# STM32H7RSxx register map
File version: 0.2
CPU: CM7 r0p1, little endian, MPU, FPU, 4 interrupt priority bits
Registers are 32-bit, read-write, reset 0x0 unless marked. A register's access mark holds for its fields unless they carry their own. Offsets are from the block's base; [hi:lo] are bit positions; {n}, {i} and the like mark numbered series.

## PSSI — Parallel synchronous slave interface
Base 0x48000400
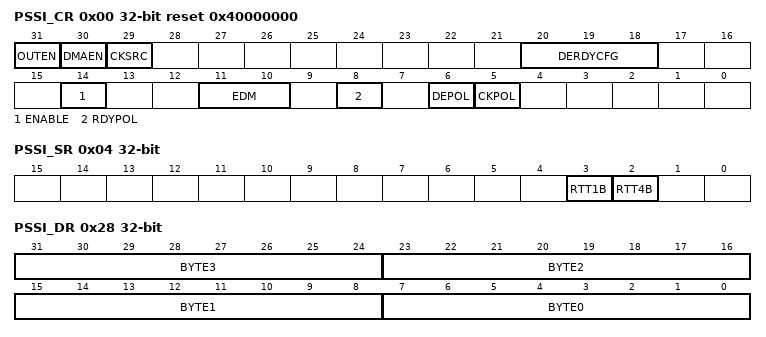
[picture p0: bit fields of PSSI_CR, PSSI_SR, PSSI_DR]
0x00 PSSI_CR reset 0x40000000 — PSSI control register
  [31] OUTEN — Data direction selection bit
    0=Receive mode: data is input synchronously with PSSI_PDCK; 1=Transmit mode: data is output synchronously with PSSI_PDCK
  [30] DMAEN — DMA enable bit
    0=DMA transfers are disabled. The user application can directly access the PSSI_DR register when DMA transfers are disabled.; 1=DMA transfers are enabled (default configuration). A DMA channel in the general-purpose DMA controller must be configured to perform transfers from/to PSSI_DR.
  [29] CKSRC — Clock source This bit configures the clock source of the PSSI_PDCK.
    0=External clock (PSSI_PDCK in input); 1=Internal clock (PSSI_PDCK in output)
  [20:18] DERDYCFG — Data enable and ready configuration When the PSSI_RDY function is mapped to the PSSI_DE pin (settings 101 or 111), it is still the RDYPOL bit which determines its polarity. Similarly, when the PSSI_DE function is mapped to the PSSI_RDY pin (settings 110 or 111), it is still the DEPOL bit which determines its polarity.
    0=PSSI_DE and PSSI_RDY both disabled; 1=Only PSSI_RDY enabled; 2=Only PSSI_DE enabled; 3=Both PSSI_RDY and PSSI_DE alternate functions enabled; 4=Both PSSI_RDY and PSSI_DE features enabled - bidirectional on PSSI_RDY pin (see Bidirectional PSSI_DE/PSSI_RDY signal on page 2965); 5=Only PSSI_RDY function enabled, but mapped to PSSI_DE pin; 6=Only PSSI_DE function enabled, but mapped to PSSI_RDY pin; 7=Both PSSI_RDY and PSSI_DE features enabled - bidirectional on PSSI_DE pin (see Bidirectional PSSI_DE/PSSI_RDY signal on page 2965)
  [14] ENABLE — PSSI enable The contents of the FIFO are flushed when ENABLE is cleared to 0. Note: When ENABLE=1, the content of PSSI_CR must not be changed, except for the ENABLE bit itself. All configuration bits can change as soon as ENABLE changes from 0 to 1. Note: The DMA controller and all PSSI configuration registers must be programmed correctly before setting the ENABLE bit to 1.
    0=PSSI disabled; 1=PSSI enabled
  [11:10] EDM — Extended data mode
    0=Interface captures 8-bit data on every parallel data clock; 1=Reserved, must not be selected; 2=Reserved, must not be selected; 3=The interface captures 16-bit data on every parallel data clock
  [8] RDYPOL — Ready (PSSI_RDY) polarity This bit indicates the level on the PSSI_RDY pin when the data are not valid on the parallel interface.
    0=PSSI_RDY active low (0 indicates that the receiver is ready to receive); 1=PSSI_RDY active high (1 indicates that the receiver is ready to receive)
  [6] DEPOL — Data enable (PSSI_DE) polarity This bit indicates the level on the PSSI_DE pin when the data are not valid on the parallel interface.
    0=PSSI_DE active low (0 indicates that data is valid); 1=PSSI_DE active high (1 indicates that data is valid)
  [5] CKPOL — Parallel data clock polarity This bit configures the capture edge of the parallel clock or the edge used for driving outputs, depending on OUTEN.
    0=Falling edge active for inputs or rising edge active for outputs; 1=Rising edge active for inputs or falling edge active for outputs
0x04 PSSI_SR ro — PSSI status register
  [3] RTT1B — FIFO is ready to transfer one byte
    1=FIFO is ready for a one byte (32-bit) transfer. In receive mode, this means that at least one valid data byte is in the FIFO. In transmit mode, this means that there is at least one byte free in the FIFO.; 0=FIFO is not ready for a 1-byte transfer
  [2] RTT4B — FIFO is ready to transfer four bytes
    1=FIFO is ready for a four-byte (32-bit) transfer. In receive mode, this means that at least four valid data bytes are in the FIFO. In transmit mode, this means that there are at least four bytes free in the FIFO.; 0=FIFO is not ready for a four-byte transfer
0x08 PSSI_RIS ro — PSSI raw interrupt status register
  [1] OVR_RIS — Data buffer overrun/underrun raw interrupt status This bit is cleared by writing a 1 to the OVR_ISC bit in PSSI_ICR.
    0=No overrun/underrun occurred; 1=An overrun/underrun occurred: overrun in receive mode, underrun in transmit mode
0x0C PSSI_IER — PSSI interrupt enable register
  [1] OVR_IE — Data buffer overrun/underrun interrupt enable
    0=No interrupt generation; 1=An interrupt is generated if either an overrun or an underrun error occurred
0x10 PSSI_MIS ro — PSSI masked interrupt status register
  [1] OVR_MIS — Data buffer overrun/underrun masked interrupt status This bit is set to 1 only when PSSI_IER/OVR_IE and PSSI_RIS/OVR_RIS are both set to 1.
    0=No interrupt is generated when an overrun/underrun error occurs; 1=An interrupt is generated if there is either an overrun or an underrun error and the OVR_IE bit is set in PSSI_IER
0x14 PSSI_ICR wo — PSSI interrupt clear register
  [1] OVR_ISC — Data buffer overrun/underrun interrupt status clear Writing this bit to 1 clears the OVR_RIS bit in PSSI_RIS.
0x28 PSSI_DR — PSSI data register
  [8n+7:8n] BYTE{n} (n=0..3) — Data byte {n}
